VERSION ""

NS_ :

BS_:

BU_: BMSMaster Converter CoolingBack CoolingLeft CoolingMotor CoolingRight Dashboard EngineLeft JETSON LightsFR LightsFL LightsRR LightsRL MPPT Pedals RCD SafeState SensorFR SensorFL SensorRR SensorRL SmallBMS Charger1 Charger2 Charger3 EngineRight CoolingLeft CoolingRight CoolingBack CoolingMotor

BO_ 3221225472 VECTOR__INDEPENDENT_SIG_MSG: 0 Vector__XXX
 SG_ BMSMaster_MasterBatteryCurrent : 23|8@0+ (0.1465,300) [-300|300] "A" Vector__XXX
 SG_ BMSMaster_MasterBatteryVoltage : 15|8@0+ (0.0059,12) [63|87] "V" Vector__XXX
 SG_ BMSMaster_MasterBatteryTemp_0000 : 47|8@0+ (0.024,50) [0|100] "C" Vector__XXX
 SG_ BMSMaster_ErrorCodeBL : 23|8@0+ (1,0) [256|65535] "" Vector__XXX
 SG_ NewSignal_0003 : 16|8@1+ (1,0) [0|0] "" Vector__XXX
 SG_ NewSignal_0002 : 8|1@1+ (1,0) [0|0] "" Vector__XXX
 SG_ NewSignal_0001 : 0|1@1+ (1,0) [0|0] "" Vector__XXX

BO_ 1952 LightsRL_NODE: 8 LightsRL

BO_ 1920 LightsRR_NODE: 8 LightsRR

BO_ 1888 LightsFL_NODE: 8 LightsFL

BO_ 1856 LightsFR_NODE: 8 LightsFR

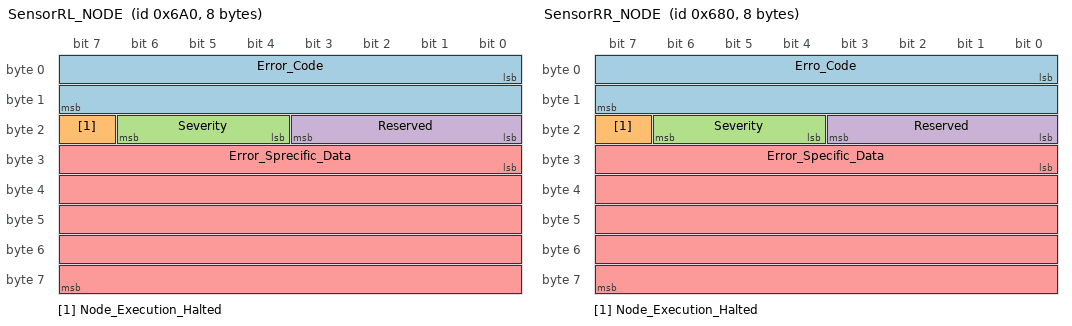
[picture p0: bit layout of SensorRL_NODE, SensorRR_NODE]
BO_ 1696 SensorRL_NODE: 8 SensorRL
 SG_ Error_Code : 0|16@1+ (1,0) [0|0] "" Vector__XXX
 SG_ Node_Execution_Halted : 23|1@1+ (1,0) [0|0] "" Vector__XXX
 SG_ Severity : 20|3@1+ (1,0) [0|0] "" Vector__XXX
 SG_ Reserved : 16|4@1+ (1,0) [0|0] "" Vector__XXX
 SG_ Error_Sprecific_Data : 24|40@1+ (1,0) [0|0] "" Vector__XXX

BO_ 1664 SensorRR_NODE: 8 SensorRR
 SG_ Erro_Code : 0|16@1+ (1,0) [0|0] "" Vector__XXX
 SG_ Node_Execution_Halted : 23|1@1+ (1,0) [0|0] "" Vector__XXX
 SG_ Severity : 20|3@1+ (1,0) [0|0] "" Vector__XXX
 SG_ Reserved : 16|4@1+ (1,0) [0|0] "" Vector__XXX
 SG_ Error_Specific_Data : 24|40@1+ (1,0) [0|0] "" Vector__XXX

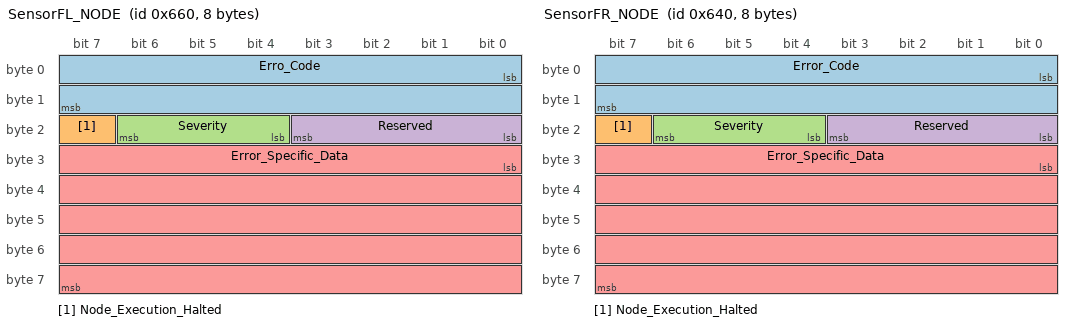
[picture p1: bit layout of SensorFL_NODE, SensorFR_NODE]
BO_ 1632 SensorFL_NODE: 8 SensorFL
 SG_ Erro_Code : 0|16@1+ (1,0) [0|0] "" Vector__XXX
 SG_ Node_Execution_Halted : 23|1@1+ (1,0) [0|0] "" Vector__XXX
 SG_ Severity : 20|3@1+ (1,0) [0|0] "" Vector__XXX
 SG_ Reserved : 16|4@1+ (1,0) [0|0] "" Vector__XXX
 SG_ Error_Specific_Data : 24|40@1+ (1,0) [0|0] "" Vector__XXX

BO_ 1600 SensorFR_NODE: 8 SensorFR
 SG_ Error_Code : 0|16@1+ (1,0) [0|0] "" Vector__XXX
 SG_ Node_Execution_Halted : 23|1@1+ (1,0) [0|0] "" Vector__XXX
 SG_ Severity : 20|3@1+ (1,0) [0|0] "" Vector__XXX
 SG_ Reserved : 16|4@1+ (1,0) [0|0] "" Vector__XXX
 SG_ Error_Specific_Data : 24|40@1+ (1,0) [0|0] "" Vector__XXX

BO_ 1472 LowVoltConverter_NODE: 8 Converter

BO_ 1120 MPPT_NODE: 8 MPPT

BO_ 864 SmallBMS_NODE: 8 SmallBMS

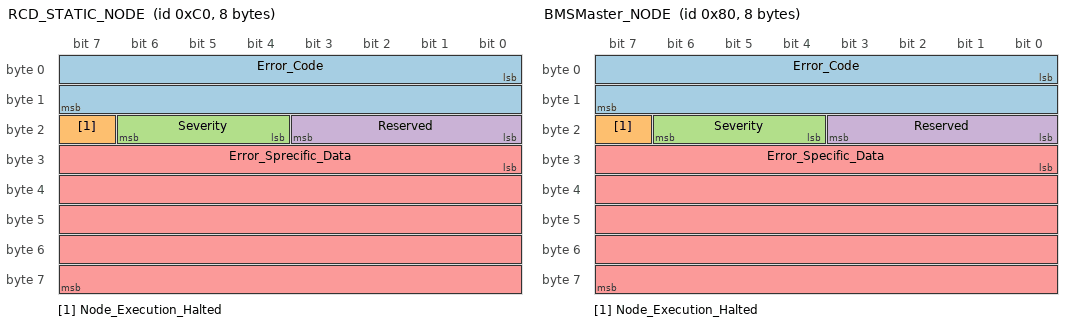
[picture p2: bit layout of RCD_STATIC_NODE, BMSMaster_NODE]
BO_ 192 RCD_STATIC_NODE: 8 RCD
 SG_ Error_Code : 0|16@1+ (1,0) [0|0] "" Vector__XXX
 SG_ Node_Execution_Halted : 23|1@1+ (1,0) [0|0] "" Vector__XXX
 SG_ Severity : 20|3@1+ (1,0) [0|0] "" Vector__XXX
 SG_ Reserved : 16|4@1+ (1,0) [0|0] "" Vector__XXX
 SG_ Error_Sprecific_Data : 24|40@1+ (1,0) [0|0] "" Vector__XXX

BO_ 128 BMSMaster_NODE: 8 BMSMaster
 SG_ Error_Code : 0|16@1+ (1,0) [0|0] "" Vector__XXX
 SG_ Node_Execution_Halted : 23|1@1+ (1,0) [0|0] "" Vector__XXX
 SG_ Severity : 20|3@1+ (1,0) [0|0] "" Vector__XXX
 SG_ Reserved : 16|4@1+ (1,0) [0|0] "" Vector__XXX
 SG_ Error_Specific_Data : 24|40@1+ (1,0) [0|0] "" Vector__XXX

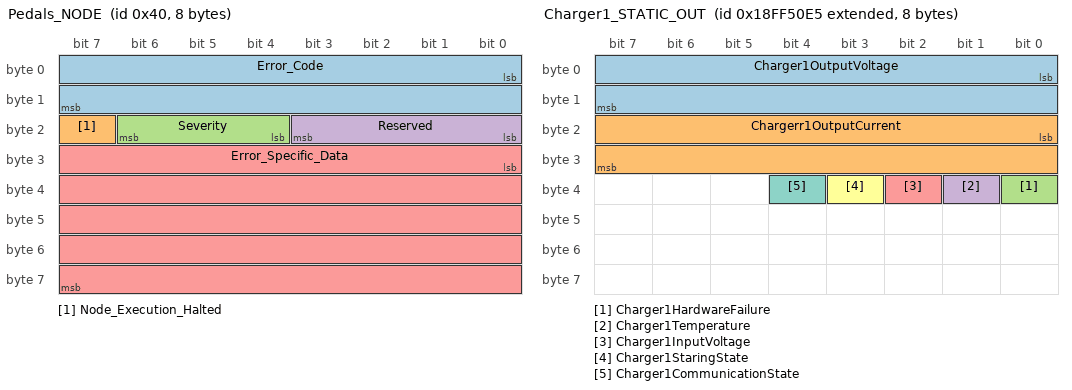
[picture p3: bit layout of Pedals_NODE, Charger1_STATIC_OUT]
BO_ 64 Pedals_NODE: 8 Pedals
 SG_ Error_Code : 0|16@1+ (1,0) [0|0] "" Vector__XXX
 SG_ Node_Execution_Halted : 23|1@1+ (1,0) [0|0] "" Vector__XXX
 SG_ Severity : 20|3@1+ (1,0) [0|0] "" Vector__XXX
 SG_ Reserved : 16|4@1+ (1,0) [0|0] "" Vector__XXX
 SG_ Error_Specific_Data : 24|40@1+ (1,0) [0|0] "" Vector__XXX

BO_ 512 JETSON_STATIC_NODE: 8 JETSON

BO_ 1 SafeState_NODE: 8 SafeState

BO_ 1983 LightsRL_END: 8 LightsRL

BO_ 1727 SensorRL_END: 8 SensorRL

BO_ 1951 LightsRR_END: 8 LightsRR

BO_ 31 SafeState_END: 8 SafeState

BO_ 95 Pedals_END: 8 Pedals

BO_ 159 BMSMaster_END: 8 BMSMaster

BO_ 223 RCD_STATIC_END: 8 RCD

BO_ 543 JETSON_STATIC_END: 8 JETSON

BO_ 895 SmallBMS_END: 8 SmallBMS

BO_ 1503 LowVoltConverter_END: 8 Converter

BO_ 1279 CoolingBack_END: 8 CoolingBack

BO_ 1311 CoolingLeft_END: 8 CoolingLeft

BO_ 1375 CoolingMotor_END: 8 CoolingMotor

BO_ 1343 CoolingRight_END: 8 CoolingRight

BO_ 1151 MPPT_END: 8 MPPT

BO_ 1653 SensorFL_END: 8 SensorFL

BO_ 1631 SensorFR_END: 8 SensorFR

BO_ 1695 SensorRR_END: 8 SensorRR

BO_ 1919 LightsFL_END: 8 LightsFL

BO_ 1887 LightsFR_END: 8 LightsFR

BO_ 2566869221 Charger1_STATIC_OUT: 8 Charger1
 SG_ Charger1OutputVoltage : 0|16@1+ (0.1,0) [440|990] "V" Vector__XXX
 SG_ Chargerr1OutputCurrent : 16|16@1+ (0.1,0) [0|400] "A" Vector__XXX
 SG_ Charger1HardwareFailure : 32|1@1+ (1,0) [0|0] "" Vector__XXX
 SG_ Charger1Temperature : 33|1@1+ (1,0) [0|0] "" Vector__XXX
 SG_ Charger1InputVoltage : 34|1@1+ (1,0) [0|0] "" Vector__XXX
 SG_ Charger1StaringState : 35|1@1+ (1,0) [0|0] "" Vector__XXX
 SG_ Charger1CommunicationState : 36|1@1+ (1,0) [0|0] "" Vector__XXX

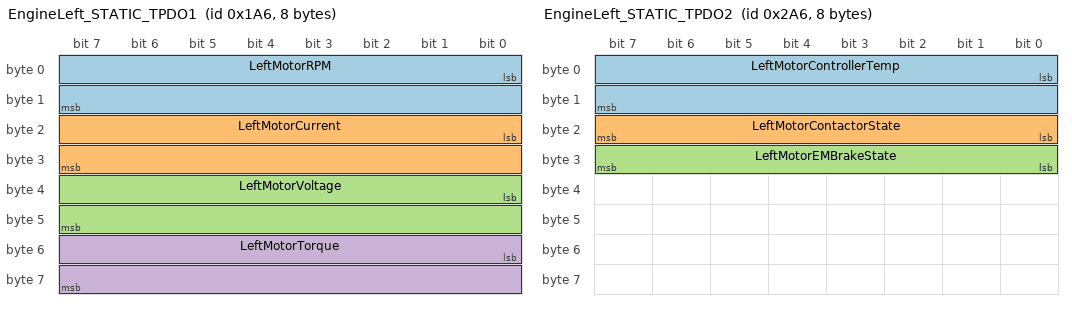
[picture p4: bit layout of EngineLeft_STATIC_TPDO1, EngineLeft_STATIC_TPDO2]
BO_ 422 EngineLeft_STATIC_TPDO1: 8 EngineLeft
 SG_ LeftMotorRPM : 0|16@1- (1,0) [-30000|30000] "rpm" Vector__XXX
 SG_ LeftMotorCurrent : 16|16@1- (0.1,0) [-32768|32767] "A" Vector__XXX
 SG_ LeftMotorVoltage : 32|16@1+ (0.01,0) [0|10500] "V" Vector__XXX
 SG_ LeftMotorTorque : 48|16@1- (1,0) [-500|500] "Nm" Vector__XXX

BO_ 678 EngineLeft_STATIC_TPDO2: 8 EngineLeft
 SG_ LeftMotorControllerTemp : 0|16@1- (0.1,0) [-1000|3000] "C" Vector__XXX
 SG_ LeftMotorContactorState : 16|8@1+ (1,0) [0|10] "" Vector__XXX
 SG_ LeftMotorEMBrakeState : 24|8@1+ (1,0) [0|4] "" Vector__XXX

BO_ 1830 EngineLeft_STATIC_NMT: 1 EngineLeft
 SG_ LeftMotorNMTState : 0|8@1+ (1,0) [0|255] "" Vector__XXX

BO_ 166 EngineLeft_STATIC_EMCY: 8 EngineLeft
 SG_ LeftMotorErrorMsg : 0|8@1+ (1,0) [0|0] "" Vector__XXX

BO_ 550 JETSON_STATIC_EngineLeft_RPDO1: 8 JETSON
 SG_ LeftMotorThrottleComand : 0|16@1- (1,0) [-32768|32767] "" Vector__XXX

BO_ 167 EngineRight_STATIC_EMCY: 8 EngineRight
 SG_ RightMotorErrorMsg : 0|8@1+ (1,0) [0|0] "" Vector__XXX

BO_ 1831 EngineRight_STATIC_NMT: 1 EngineRight
 SG_ RightMotorNMTState : 0|8@1+ (1,0) [0|255] "" Vector__XXX

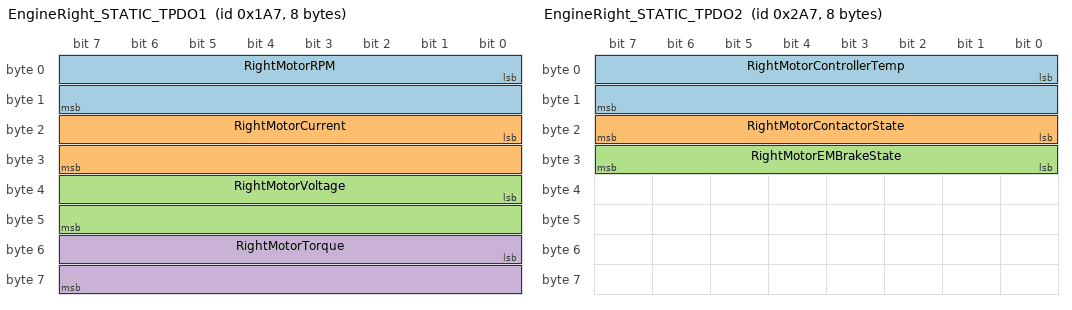
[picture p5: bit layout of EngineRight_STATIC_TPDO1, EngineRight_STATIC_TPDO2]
BO_ 423 EngineRight_STATIC_TPDO1: 8 EngineRight
 SG_ RightMotorRPM : 0|16@1- (1,0) [-30000|30000] "rpm" Vector__XXX
 SG_ RightMotorCurrent : 16|16@1- (0.1,0) [-32768|32767] "A" Vector__XXX
 SG_ RightMotorVoltage : 32|16@1+ (0.01,0) [0|10500] "V" Vector__XXX
 SG_ RightMotorTorque : 48|16@1- (1,0) [-500|500] "Nm" Vector__XXX

BO_ 679 EngineRight_STATIC_TPDO2: 8 EngineRight
 SG_ RightMotorControllerTemp : 0|16@1- (0.1,0) [-1000|3000] "C" Vector__XXX
 SG_ RightMotorContactorState : 16|8@1+ (1,0) [0|10] "" Vector__XXX
 SG_ RightMotorEMBrakeState : 24|8@1+ (1,0) [0|4] "" Vector__XXX

BO_ 551 JETSON_STATIC_EngineRight_RPDO1: 8 JETSON
 SG_ RightMotorThrottleComand : 0|16@1- (1,0) [-32768|32767] "" Vector__XXX

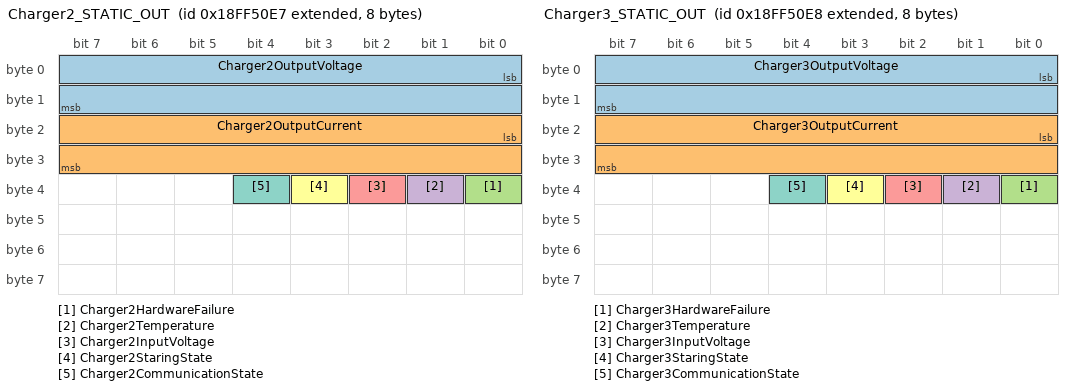
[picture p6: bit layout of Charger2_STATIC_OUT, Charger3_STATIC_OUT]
BO_ 2566869223 Charger2_STATIC_OUT: 8 Charger2
 SG_ Charger2OutputVoltage : 0|16@1+ (0.1,0) [440|900] "V" Vector__XXX
 SG_ Charger2OutputCurrent : 16|16@1+ (0.1,0) [0|400] "A" Vector__XXX
 SG_ Charger2HardwareFailure : 32|1@1+ (1,0) [0|0] "" Vector__XXX
 SG_ Charger2Temperature : 33|1@1+ (1,0) [0|0] "" Vector__XXX
 SG_ Charger2InputVoltage : 34|1@1+ (1,0) [0|0] "" Vector__XXX
 SG_ Charger2StaringState : 35|1@1+ (1,0) [0|0] "" Vector__XXX
 SG_ Charger2CommunicationState : 36|1@1+ (1,0) [0|0] "" Vector__XXX

BO_ 2566869224 Charger3_STATIC_OUT: 8 Charger3
 SG_ Charger3OutputVoltage : 0|16@1+ (0.1,0) [440|990] "V" Vector__XXX
 SG_ Charger3OutputCurrent : 16|16@1+ (0.1,0) [0|400] "A" Vector__XXX
 SG_ Charger3HardwareFailure : 32|1@1+ (1,0) [0|0] "" Vector__XXX
 SG_ Charger3Temperature : 33|1@1+ (1,0) [0|0] "" Vector__XXX
 SG_ Charger3InputVoltage : 34|1@1+ (1,0) [0|0] "" Vector__XXX
 SG_ Charger3StaringState : 35|1@1+ (1,0) [0|0] "" Vector__XXX
 SG_ Charger3CommunicationState : 36|1@1+ (1,0) [0|0] "" Vector__XXX

BO_ 2550588916 RCD_STATIC_Charger1Comms: 8 RCD
 SG_ MaxChargVolt : 7|16@0+ (0.1,0) [0|0] "V" Vector__XXX
 SG_ MaxChargCurr : 23|16@0+ (0.1,0) [0|0] "A" Vector__XXX
 SG_ Control : 39|8@0+ (0.1,0) [0|0] "" Vector__XXX

BO_ 2550589428 RCD_STATIC_Charger2Comms: 8 RCD
 SG_ MaxChargVolt : 7|16@0+ (0.1,0) [0|0] "V" Vector__XXX
 SG_ MaxChargCurr : 23|16@0+ (0.1,0) [0|0] "A" Vector__XXX
 SG_ Control : 39|8@0+ (0.1,0) [0|0] "" Vector__XXX

BO_ 2550589684 RCD_STATIC_Charger3Comms: 8 RCD
 SG_ MaxChargVolt : 7|16@0+ (0.1,0) [0|0] "V" Vector__XXX
 SG_ MaxChargCurr : 23|16@0+ (0.1,0) [0|0] "A" Vector__XXX
 SG_ Control : 39|8@0+ (0.1,0) [0|0] "" Vector__XXX

BO_ 130 BMSMaster_MasterVoltCurrTemp: 6 BMSMaster
 SG_ BMSMaster_MasterBatteryVoltage : 0|16@1+ (0.1,0) [63|87] "V"  RCD
 SG_ BMSMaster_MasterBatteryCurrent : 16|16@1- (0.1,0) [-300|300] "A"  RCD
 SG_ BMSMaste_MasterBatteryTemperatur : 32|16@1+ (0.01,0) [0|100] "C"  RCD

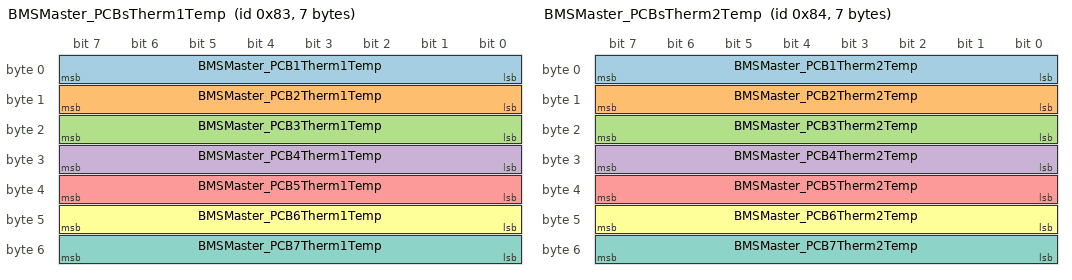
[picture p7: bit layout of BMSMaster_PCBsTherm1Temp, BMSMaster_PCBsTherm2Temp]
BO_ 131 BMSMaster_PCBsTherm1Temp: 7 BMSMaster
 SG_ BMSMaster_PCB1Therm1Temp : 0|8@1+ (0.39216,49.8039) [0|100] "C" Vector__XXX
 SG_ BMSMaster_PCB2Therm1Temp : 8|8@1+ (0.39216,49.8039) [0|100] "C" Vector__XXX
 SG_ BMSMaster_PCB3Therm1Temp : 16|8@1+ (0.39216,49.8039) [0|100] "C" Vector__XXX
 SG_ BMSMaster_PCB4Therm1Temp : 24|8@1+ (0.39216,49.8039) [0|100] "C" Vector__XXX
 SG_ BMSMaster_PCB5Therm1Temp : 32|8@1+ (0.39216,49.8039) [0|100] "C" Vector__XXX
 SG_ BMSMaster_PCB6Therm1Temp : 40|8@1+ (0.39216,49.8039) [0|100] "C" Vector__XXX
 SG_ BMSMaster_PCB7Therm1Temp : 48|8@1+ (0.39216,49.8039) [0|100] "C" Vector__XXX

BO_ 132 BMSMaster_PCBsTherm2Temp: 7 BMSMaster
 SG_ BMSMaster_PCB1Therm2Temp : 0|8@1+ (0.39216,49.8039) [0|100] "C" Vector__XXX
 SG_ BMSMaster_PCB2Therm2Temp : 8|8@1+ (0.39216,49.8039) [0|100] "C" Vector__XXX
 SG_ BMSMaster_PCB3Therm2Temp : 16|8@1+ (0.39216,49.8039) [0|100] "C" Vector__XXX
 SG_ BMSMaster_PCB4Therm2Temp : 24|8@1+ (0.39216,49.8039) [0|100] "C" Vector__XXX
 SG_ BMSMaster_PCB5Therm2Temp : 32|8@1+ (0.39216,49.8039) [0|100] "C" Vector__XXX
 SG_ BMSMaster_PCB6Therm2Temp : 40|8@1+ (0.39216,49.8039) [0|100] "C" Vector__XXX
 SG_ BMSMaster_PCB7Therm2Temp : 48|8@1+ (0.39216,49.8039) [0|100] "C" Vector__XXX

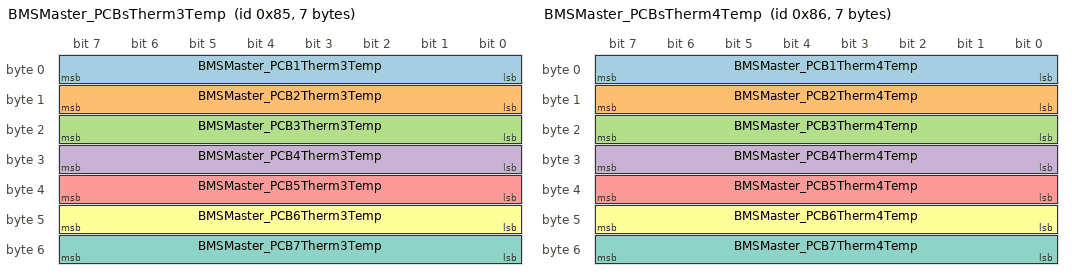
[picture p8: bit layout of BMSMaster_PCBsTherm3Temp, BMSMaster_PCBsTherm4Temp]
BO_ 133 BMSMaster_PCBsTherm3Temp: 7 BMSMaster
 SG_ BMSMaster_PCB1Therm3Temp : 0|8@1+ (0.39216,49) [0|100] "C" Vector__XXX
 SG_ BMSMaster_PCB2Therm3Temp : 8|8@1+ (0.39216,49) [0|100] "C" Vector__XXX
 SG_ BMSMaster_PCB3Therm3Temp : 16|8@1+ (0.39216,49) [0|100] "C" Vector__XXX
 SG_ BMSMaster_PCB4Therm3Temp : 24|8@1+ (0.39216,49) [0|100] "C" Vector__XXX
 SG_ BMSMaster_PCB5Therm3Temp : 32|8@1+ (0.39216,49) [0|100] "C" Vector__XXX
 SG_ BMSMaster_PCB6Therm3Temp : 40|8@1+ (0.39216,49) [0|100] "C" Vector__XXX
 SG_ BMSMaster_PCB7Therm3Temp : 48|8@1+ (0.39216,49) [0|100] "C" Vector__XXX

BO_ 134 BMSMaster_PCBsTherm4Temp: 7 BMSMaster
 SG_ BMSMaster_PCB1Therm4Temp : 0|8@1+ (0.39216,49.8039) [0|100] "C" Vector__XXX
 SG_ BMSMaster_PCB2Therm4Temp : 8|8@1+ (0.39216,49.8039) [0|100] "C" Vector__XXX
 SG_ BMSMaster_PCB3Therm4Temp : 16|8@1+ (0.39216,49.8039) [0|100] "C" Vector__XXX
 SG_ BMSMaster_PCB4Therm4Temp : 24|8@1+ (0.39216,49.8039) [0|100] "C" Vector__XXX
 SG_ BMSMaster_PCB5Therm4Temp : 32|8@1+ (0.39216,49.8039) [0|100] "C" Vector__XXX
 SG_ BMSMaster_PCB6Therm4Temp : 40|8@1+ (0.39216,49.8039) [0|100] "C" Vector__XXX
 SG_ BMSMaster_PCB7Therm4Temp : 48|8@1+ (0.39216,49.8039) [0|100] "C" Vector__XXX

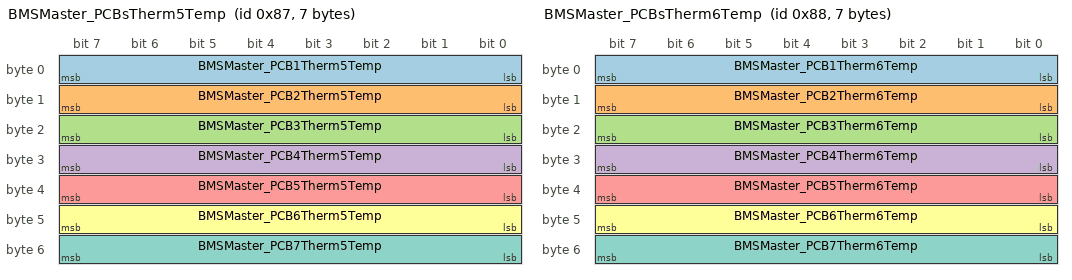
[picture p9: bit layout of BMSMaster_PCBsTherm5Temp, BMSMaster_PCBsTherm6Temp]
BO_ 135 BMSMaster_PCBsTherm5Temp: 7 BMSMaster
 SG_ BMSMaster_PCB1Therm5Temp : 0|8@1+ (0.39216,49.8039) [0|100] "C" Vector__XXX
 SG_ BMSMaster_PCB2Therm5Temp : 8|8@1+ (0.39216,49.8039) [0|100] "C" Vector__XXX
 SG_ BMSMaster_PCB3Therm5Temp : 16|8@1+ (0.39216,49.8039) [0|100] "C" Vector__XXX
 SG_ BMSMaster_PCB4Therm5Temp : 24|8@1+ (0.39216,49.8039) [0|100] "C" Vector__XXX
 SG_ BMSMaster_PCB5Therm5Temp : 32|8@1+ (0.39216,49.8039) [0|100] "C" Vector__XXX
 SG_ BMSMaster_PCB6Therm5Temp : 40|8@1+ (0.39216,49.8039) [0|100] "C" Vector__XXX
 SG_ BMSMaster_PCB7Therm5Temp : 48|8@1+ (0.39216,49.8039) [0|100] "C" Vector__XXX

BO_ 136 BMSMaster_PCBsTherm6Temp: 7 BMSMaster
 SG_ BMSMaster_PCB1Therm6Temp : 0|8@1+ (0.39216,49.8039) [0|100] "C" Vector__XXX
 SG_ BMSMaster_PCB2Therm6Temp : 8|8@1+ (0.39216,49.8039) [0|100] "C" Vector__XXX
 SG_ BMSMaster_PCB3Therm6Temp : 16|8@1+ (0.39216,49.8039) [0|100] "C" Vector__XXX
 SG_ BMSMaster_PCB4Therm6Temp : 24|8@1+ (0.39216,49.8039) [0|100] "C" Vector__XXX
 SG_ BMSMaster_PCB5Therm6Temp : 32|8@1+ (0.39216,49.8039) [0|100] "C" Vector__XXX
 SG_ BMSMaster_PCB6Therm6Temp : 40|8@1+ (0.39216,49.8039) [0|100] "C" Vector__XXX
 SG_ BMSMaster_PCB7Therm6Temp : 48|8@1+ (0.39216,49.8039) [0|100] "C" Vector__XXX

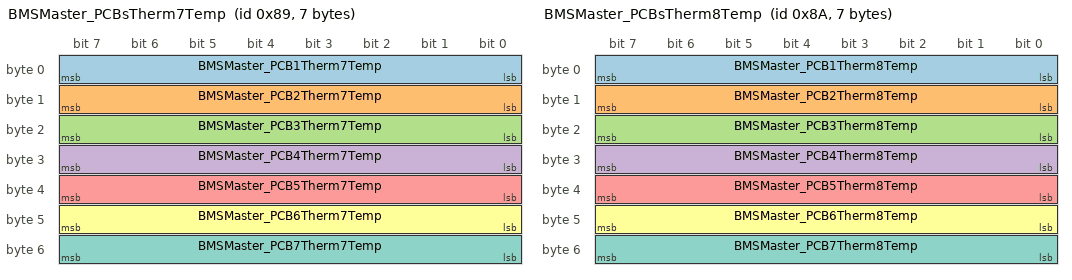
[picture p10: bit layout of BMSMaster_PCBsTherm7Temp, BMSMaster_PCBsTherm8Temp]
BO_ 137 BMSMaster_PCBsTherm7Temp: 7 BMSMaster
 SG_ BMSMaster_PCB1Therm7Temp : 0|8@1+ (0.39216,49) [0|100] "C" Vector__XXX
 SG_ BMSMaster_PCB2Therm7Temp : 8|8@1+ (0.39216,49.8039) [0|100] "C" Vector__XXX
 SG_ BMSMaster_PCB3Therm7Temp : 16|8@1+ (0.39216,49.8039) [0|100] "C" Vector__XXX
 SG_ BMSMaster_PCB4Therm7Temp : 24|8@1+ (0.39216,49.8039) [0|100] "C" Vector__XXX
 SG_ BMSMaster_PCB5Therm7Temp : 32|8@1+ (0.39216,49.8039) [0|100] "C" Vector__XXX
 SG_ BMSMaster_PCB6Therm7Temp : 40|8@1+ (0.39216,49.8039) [0|100] "C" Vector__XXX
 SG_ BMSMaster_PCB7Therm7Temp : 48|8@1+ (0.39216,49.8039) [0|100] "C" Vector__XXX

BO_ 138 BMSMaster_PCBsTherm8Temp: 7 BMSMaster
 SG_ BMSMaster_PCB1Therm8Temp : 0|8@1+ (0.39216,49) [0|100] "C" Vector__XXX
 SG_ BMSMaster_PCB2Therm8Temp : 8|8@1+ (0.39216,49) [0|100] "C" Vector__XXX
 SG_ BMSMaster_PCB3Therm8Temp : 16|8@1+ (0.39216,49) [0|100] "C" Vector__XXX
 SG_ BMSMaster_PCB4Therm8Temp : 24|8@1+ (0.39216,49) [0|100] "C" Vector__XXX
 SG_ BMSMaster_PCB5Therm8Temp : 32|8@1+ (0.39216,49) [0|100] "C" Vector__XXX
 SG_ BMSMaster_PCB6Therm8Temp : 40|8@1+ (0.39216,49) [0|100] "C" Vector__XXX
 SG_ BMSMaster_PCB7Therm8Temp : 48|8@1+ (0.39216,49) [0|100] "C" Vector__XXX

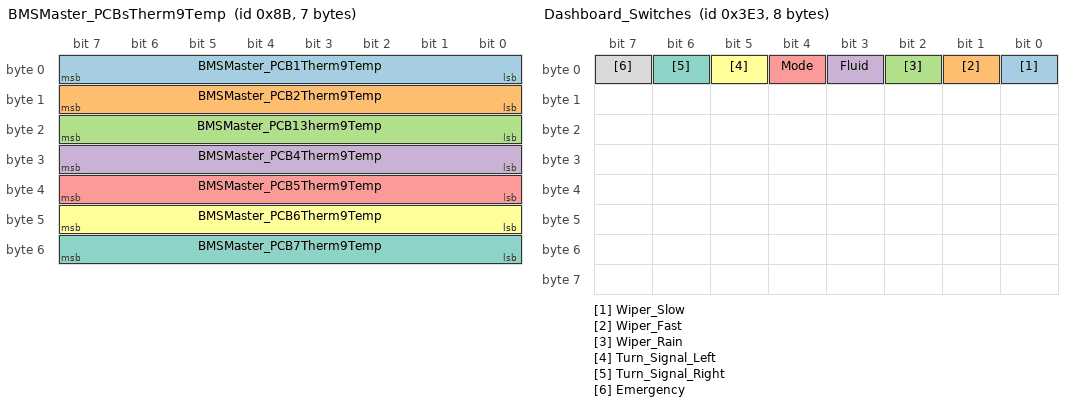
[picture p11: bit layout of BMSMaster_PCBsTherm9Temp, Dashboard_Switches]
BO_ 139 BMSMaster_PCBsTherm9Temp: 7 BMSMaster
 SG_ BMSMaster_PCB1Therm9Temp : 0|8@1+ (0.39216,49) [0|100] "C" Vector__XXX
 SG_ BMSMaster_PCB2Therm9Temp : 8|8@1+ (0.39216,49) [0|100] "C" Vector__XXX
 SG_ BMSMaster_PCB13herm9Temp : 16|8@1+ (0.39216,49) [0|100] "C" Vector__XXX
 SG_ BMSMaster_PCB4Therm9Temp : 24|8@1+ (0.39216,49) [0|100] "C" Vector__XXX
 SG_ BMSMaster_PCB5Therm9Temp : 32|8@1+ (0.39216,49) [0|100] "C" Vector__XXX
 SG_ BMSMaster_PCB6Therm9Temp : 40|8@1+ (0.39216,49) [0|100] "C" Vector__XXX
 SG_ BMSMaster_PCB7Therm9Temp : 48|8@1+ (0.39216,49) [0|100] "C" Vector__XXX

BO_ 993 Dashboard_Control: 8 Dashboard
 SG_ Absolute_Encoder : 0|14@1+ (0.06591796875,540) [-540|540] "deg"  RCD
 SG_ PRND : 14|8@1+ (1,0) [0|3] ""  RCD

BO_ 994 Dashboard_Important: 8 Dashboard
 SG_ Light_Switch : 0|8@1+ (1,0) [0|3] "" Vector__XXX
 SG_ Rain_Level : 8|8@1+ (1,0) [0|4] "" Vector__XXX

BO_ 995 Dashboard_Switches: 8 Dashboard
 SG_ Wiper_Slow : 0|1@1+ (1,0) [0|1] "" Vector__XXX
 SG_ Wiper_Fast : 1|1@1+ (1,0) [0|1] "" Vector__XXX
 SG_ Wiper_Rain : 2|1@1+ (1,0) [0|1] "" Vector__XXX
 SG_ Fluid : 3|1@1+ (1,0) [0|1] "" Vector__XXX
 SG_ Mode : 4|1@1+ (1,0) [0|1] "" Vector__XXX
 SG_ Turn_Signal_Left : 5|1@1+ (1,0) [0|3] "" Vector__XXX
 SG_ Turn_Signal_Right : 6|1@1+ (1,0) [0|0] "" Vector__XXX
 SG_ Emergency : 7|1@1+ (1,0) [0|1] "" Vector__XXX

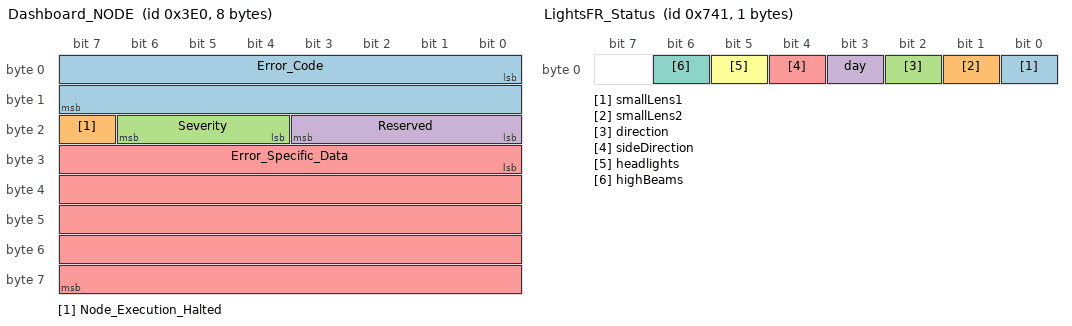
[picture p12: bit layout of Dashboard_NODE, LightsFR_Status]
BO_ 992 Dashboard_NODE: 8 Dashboard
 SG_ Error_Code : 0|16@1+ (1,0) [0|0] "" Vector__XXX
 SG_ Node_Execution_Halted : 23|1@1+ (1,0) [0|0] "" Vector__XXX
 SG_ Severity : 20|3@1+ (1,0) [0|0] "" Vector__XXX
 SG_ Reserved : 16|4@1+ (1,0) [0|0] "" Vector__XXX
 SG_ Error_Specific_Data : 24|40@1+ (1,0) [0|0] "" Vector__XXX

BO_ 1023 Dashboard_END: 8 Dashboard

BO_ 1857 LightsFR_Status: 1 LightsFR
 SG_ smallLens1 : 0|1@1+ (1,0) [0|0] "" Vector__XXX
 SG_ smallLens2 : 1|1@1+ (1,0) [0|0] "" Vector__XXX
 SG_ direction : 2|1@1+ (1,0) [0|0] "" Vector__XXX
 SG_ day : 3|1@1+ (1,0) [0|0] "" Vector__XXX
 SG_ sideDirection : 4|1@1+ (1,0) [0|0] "" Vector__XXX
 SG_ headlights : 5|1@1+ (1,0) [0|0] "" Vector__XXX
 SG_ highBeams : 6|1@1+ (1,0) [0|0] "" Vector__XXX

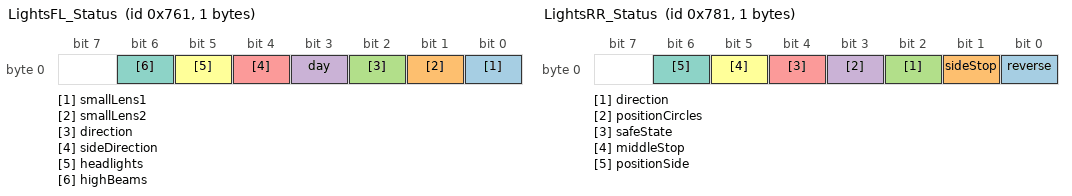
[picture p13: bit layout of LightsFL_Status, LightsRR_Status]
BO_ 1889 LightsFL_Status: 1 LightsFL
 SG_ smallLens1 : 0|1@1+ (1,0) [0|0] "" Vector__XXX
 SG_ smallLens2 : 1|1@1+ (1,0) [0|0] "" Vector__XXX
 SG_ direction : 2|1@1+ (1,0) [0|0] "" Vector__XXX
 SG_ day : 3|1@1+ (1,0) [0|0] "" Vector__XXX
 SG_ sideDirection : 4|1@1+ (1,0) [0|0] "" Vector__XXX
 SG_ headlights : 5|1@1+ (1,0) [0|0] "" Vector__XXX
 SG_ highBeams : 6|1@1+ (1,0) [0|0] "" Vector__XXX

BO_ 1921 LightsRR_Status: 1 LightsRR
 SG_ reverse : 0|1@1+ (1,0) [0|0] "" Vector__XXX
 SG_ sideStop : 1|1@1+ (1,0) [0|0] "" Vector__XXX
 SG_ direction : 2|1@1+ (1,0) [0|0] "" Vector__XXX
 SG_ positionCircles : 3|1@1+ (1,0) [0|0] "" Vector__XXX
 SG_ safeState : 4|1@1+ (1,0) [0|0] "" Vector__XXX
 SG_ middleStop : 5|1@1+ (1,0) [0|0] "" Vector__XXX
 SG_ positionSide : 6|1@1+ (1,0) [0|0] "" Vector__XXX

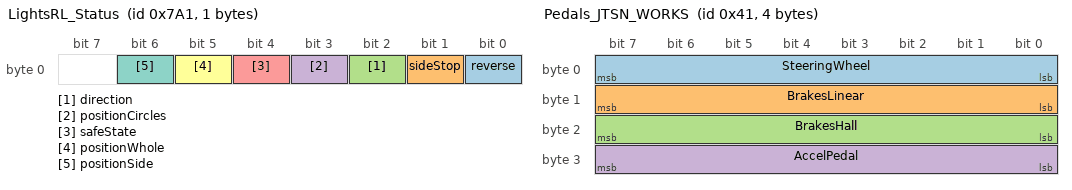
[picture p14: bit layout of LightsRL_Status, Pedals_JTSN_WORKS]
BO_ 1953 LightsRL_Status: 1 LightsRL
 SG_ reverse : 0|1@1+ (1,0) [0|0] "" Vector__XXX
 SG_ sideStop : 1|1@1+ (1,0) [0|0] "" Vector__XXX
 SG_ direction : 2|1@1+ (1,0) [0|0] "" Vector__XXX
 SG_ positionCircles : 3|1@1+ (1,0) [0|0] "" Vector__XXX
 SG_ safeState : 4|1@1+ (1,0) [0|0] "" Vector__XXX
 SG_ positionWhole : 5|1@1+ (1,0) [0|0] "" Vector__XXX
 SG_ positionSide : 6|1@1+ (1,0) [0|0] "" Vector__XXX

BO_ 1601 SensorFR_Wheel_Speed: 2 SensorFR
 SG_ SensorFR_Wheel_Speed : 0|16@1+ (0.000839,0) [0|55] "m/s" Vector__XXX

BO_ 1602 SensorFR_Suspension: 2 SensorFR
 SG_ SensorFR_Suspension : 0|16@1+ (0.02,0) [0|75] "mm" Vector__XXX

BO_ 1603 SensorFR_Door_Sensor: 1 SensorFR
 SG_ SensorFR_Door_Sensor : 0|1@1+ (1,0) [0|1] "" Vector__XXX

BO_ 1633 SensorFL_Wheel_Speed: 2 SensorFL
 SG_ SensorFL_Wheel_Speed : 0|16@1+ (0.000839,0) [0|55] "m/s" Vector__XXX

BO_ 1634 SensorFL_Suspension: 2 SensorFL
 SG_ SensorFL_Suspension : 0|16@1+ (0.02,0) [0|75] "mm" Vector__XXX

BO_ 1635 SensorFL_Door_Sensor: 1 SensorFL
 SG_ SensorFL_Door_Sensor : 0|1@1+ (1,0) [0|1] "" Vector__XXX

BO_ 1665 SensorRR_Wheel_Speed: 2 SensorRR
 SG_ SensorRR_Wheel_Speed : 0|16@1+ (0.000839,0) [0|55] "m/s" Vector__XXX

BO_ 1666 SensorRR_Suspension: 2 SensorRR
 SG_ SensorRR_Suspension : 0|16@1+ (0.02,0) [0|75] "mm" Vector__XXX

BO_ 1667 SensorRR_Door_Sensor: 1 SensorRR
 SG_ SensorRR_Door_Sensor : 0|1@1+ (1,0) [0|1] "" Vector__XXX

BO_ 1697 SensorRL_Wheel_Speed: 2 SensorRL
 SG_ SensorRL_Wheel_Speed : 0|16@1+ (0.000839,0) [0|55] "m/s" Vector__XXX

BO_ 1698 SensorRL_Suspension: 2 SensorRL
 SG_ SensorRL_Suspension : 0|16@1+ (0.02,0) [0|55] "m/s" Vector__XXX

BO_ 1699 SensorRL_Door_Sensor: 1 SensorRL
 SG_ SensorRL_Door_Sensor : 0|1@1+ (1,0) [0|1] "" Vector__XXX

BO_ 65 Pedals_JTSN_WORKS: 4 Pedals
 SG_ SteeringWheel : 0|8@1+ (1,0) [0|100] "%" Vector__XXX
 SG_ BrakesLinear : 8|8@1+ (1,0) [0|100] "%" Vector__XXX
 SG_ BrakesHall : 16|8@1+ (1,0) [0|100] "%" Vector__XXX
 SG_ AccelPedal : 24|8@1+ (1,0) [0|100] "%" Vector__XXX

BO_ 0 Pedals_STATIC_EnginesNMT: 2 Pedals
 SG_ NMT_Command : 0|8@1+ (1,0) [0|255] "-" Vector__XXX
 SG_ NodeID : 8|8@1+ (1,0) [0|255] "-" Vector__XXX

BO_ 1249 CoolingBack_Fan: 8 CoolingBack
 SG_ CoolingBack_SpeedF1 : 0|8@1+ (1,0) [0|100] "" Vector__XXX
 SG_ CoolingBack_SpeedF2 : 8|8@1+ (1,0) [0|100] "" Vector__XXX

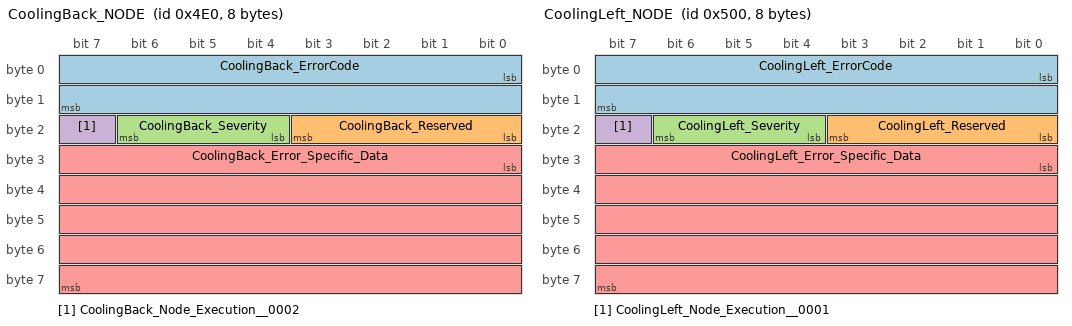
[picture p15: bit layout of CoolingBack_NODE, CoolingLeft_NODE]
BO_ 1248 CoolingBack_NODE: 8 CoolingBack
 SG_ CoolingBack_ErrorCode : 0|16@1+ (1,0) [0|0] "" Vector__XXX
 SG_ CoolingBack_Reserved : 16|4@1+ (1,0) [0|0] "" Vector__XXX
 SG_ CoolingBack_Severity : 20|3@1+ (1,0) [0|0] "" Vector__XXX
 SG_ CoolingBack_Node_Execution__0002 : 23|1@1+ (1,0) [0|0] "" Vector__XXX
 SG_ CoolingBack_Error_Specific_Data : 24|40@1+ (1,0) [0|0] "" Vector__XXX

BO_ 1282 CoolingLeft_Fan: 8 CoolingLeft
 SG_ CoolingLeft_SpeedF1 : 0|8@1+ (1,0) [0|100] "" Vector__XXX
 SG_ CoolingLeft_SpeedF2 : 8|8@1+ (1,0) [0|100] "" Vector__XXX

BO_ 1280 CoolingLeft_NODE: 8 CoolingLeft
 SG_ CoolingLeft_ErrorCode : 0|16@1+ (1,0) [0|0] "" Vector__XXX
 SG_ CoolingLeft_Reserved : 16|4@1+ (1,0) [0|0] "" Vector__XXX
 SG_ CoolingLeft_Severity : 20|3@1+ (1,0) [0|0] "" Vector__XXX
 SG_ CoolingLeft_Node_Execution__0001 : 23|1@1+ (1,0) [0|0] "" Vector__XXX
 SG_ CoolingLeft_Error_Specific_Data : 24|40@1+ (1,0) [0|0] "" Vector__XXX

BO_ 1281 CoolingLeft_Sensor: 8 CoolingLeft
 SG_ CoolingLeft_Sensor_Temp : 0|16@1- (1,0) [-40|80] "C" Vector__XXX
 SG_ CoolingLeft_Sensor_RH : 16|16@1+ (1,0) [0|99.9] "" Vector__XXX

BO_ 1283 CoolingLeft_Serwo: 8 CoolingLeft
 SG_ CoolingLeft_PosSerwo1 : 0|8@1+ (1,0) [0|100] "" Vector__XXX
 SG_ CoolingLeft_PosSerwo2 : 8|8@1+ (1,0) [0|100] "" Vector__XXX

BO_ 1346 CoolingMotor_Fan: 8 CoolingMotor
 SG_ CoolingMotor_SpeedF1 : 0|8@1+ (1,0) [0|100] "" Vector__XXX
 SG_ CoolingMotor_SpeedF2 : 8|8@1+ (1,0) [0|100] "" Vector__XXX

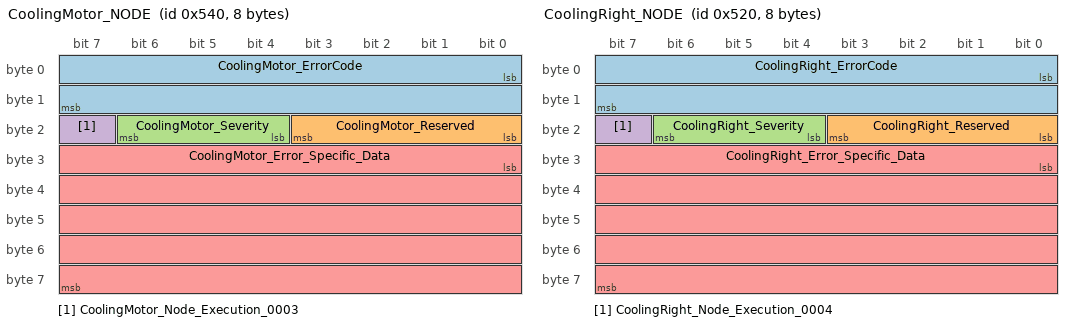
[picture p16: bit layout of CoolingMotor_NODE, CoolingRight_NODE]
BO_ 1344 CoolingMotor_NODE: 8 CoolingMotor
 SG_ CoolingMotor_ErrorCode : 0|16@1+ (1,0) [0|0] "" Vector__XXX
 SG_ CoolingMotor_Reserved : 16|4@1+ (1,0) [0|0] "" Vector__XXX
 SG_ CoolingMotor_Severity : 20|3@1+ (1,0) [0|0] "" Vector__XXX
 SG_ CoolingMotor_Node_Execution_0003 : 23|1@1+ (1,0) [0|0] "" Vector__XXX
 SG_ CoolingMotor_Error_Specific_Data : 24|40@1+ (1,0) [0|0] "" Vector__XXX

BO_ 1345 CoolingMotor_Sensor: 8 CoolingMotor
 SG_ CoolingMotor_Sensor_Temp : 0|16@1- (1,0) [-40|80] "C" Vector__XXX
 SG_ CoolingMotor_Sensor_RH : 16|16@1+ (1,0) [0|99.9] "" Vector__XXX

BO_ 1347 CoolingMotor_Serwo: 8 CoolingMotor
 SG_ CoolingMotor_PosSerwo1 : 0|8@1+ (1,0) [0|100] "" Vector__XXX
 SG_ CoolingMotor_PosSerwo2 : 8|8@1+ (1,0) [0|100] "" Vector__XXX

BO_ 1314 CoolingRight_Fan: 8 CoolingRight
 SG_ CoolingRight_SpeedF1 : 0|8@1+ (1,0) [0|100] "" Vector__XXX
 SG_ CoolingRight_SpeedF2 : 8|8@1+ (1,0) [0|100] "" Vector__XXX

BO_ 1312 CoolingRight_NODE: 8 CoolingRight
 SG_ CoolingRight_ErrorCode : 0|16@1+ (1,0) [0|0] "" Vector__XXX
 SG_ CoolingRight_Reserved : 16|4@1+ (1,0) [0|0] "" Vector__XXX
 SG_ CoolingRight_Severity : 20|3@1+ (1,0) [0|0] "" Vector__XXX
 SG_ CoolingRight_Node_Execution_0004 : 23|1@1+ (1,0) [0|0] "" Vector__XXX
 SG_ CoolingRight_Error_Specific_Data : 24|40@1+ (1,0) [0|0] "" Vector__XXX

BO_ 1313 CoolingRight_Sensor: 8 CoolingRight
 SG_ CoolingRight_Sensor_Temp : 0|16@1- (1,0) [-40|80] "C" Vector__XXX
 SG_ CoolingRight_Sensor_RH : 16|16@1+ (1,0) [0|99.9] "" Vector__XXX

BO_ 1315 CoolingRight_Serwo: 8 CoolingRight
 SG_ CoolingRight_PosSerwo1 : 0|8@1+ (1,0) [0|100] "" Vector__XXX
 SG_ CoolingRight_PosSerwo2 : 8|8@1+ (1,0) [0|100] "" Vector__XXX

BO_ 193 RCD_Status: 8 RCD
 SG_ ChargingPortStatus : 0|2@1+ (1,0) [0|0] "" Vector__XXX

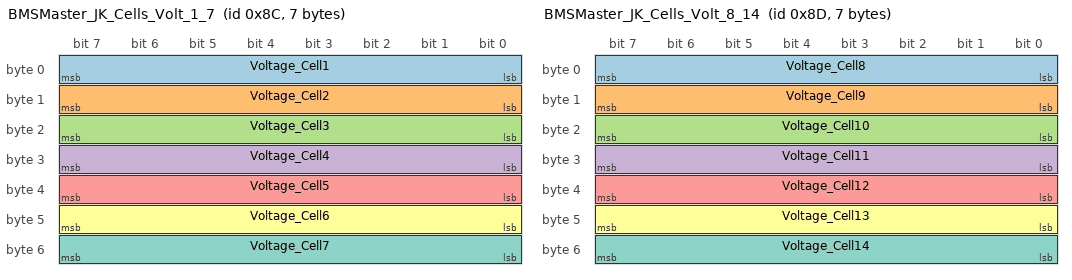
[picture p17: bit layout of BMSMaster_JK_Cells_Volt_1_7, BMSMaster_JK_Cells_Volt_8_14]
BO_ 140 BMSMaster_JK_Cells_Volt_1_7: 7 BMSMaster
 SG_ Voltage_Cell1 : 0|8@1+ (0.01,0) [0|425] "V" Vector__XXX
 SG_ Voltage_Cell2 : 8|8@1+ (0.01,0) [0|425] "V" Vector__XXX
 SG_ Voltage_Cell3 : 16|8@1+ (0.01,0) [0|425] "V" Vector__XXX
 SG_ Voltage_Cell4 : 24|8@1+ (0.01,0) [0|425] "V" Vector__XXX
 SG_ Voltage_Cell5 : 32|8@1+ (0.01,0) [0|425] "V" Vector__XXX
 SG_ Voltage_Cell6 : 40|8@1+ (0.01,0) [0|425] "V" Vector__XXX
 SG_ Voltage_Cell7 : 48|8@1+ (0.01,0) [0|425] "V" Vector__XXX

BO_ 141 BMSMaster_JK_Cells_Volt_8_14: 7 BMSMaster
 SG_ Voltage_Cell8 : 0|8@1+ (0.01,0) [0|425] "V" Vector__XXX
 SG_ Voltage_Cell9 : 8|8@1+ (0.01,0) [0|425] "V" Vector__XXX
 SG_ Voltage_Cell10 : 16|8@1+ (0.01,0) [0|425] "V" Vector__XXX
 SG_ Voltage_Cell11 : 24|8@1+ (0.01,0) [0|425] "V" Vector__XXX
 SG_ Voltage_Cell12 : 32|8@1+ (0.01,0) [0|425] "V" Vector__XXX
 SG_ Voltage_Cell13 : 40|8@1+ (0.01,0) [0|425] "V" Vector__XXX
 SG_ Voltage_Cell14 : 48|8@1+ (0.01,0) [0|425] "V" Vector__XXX

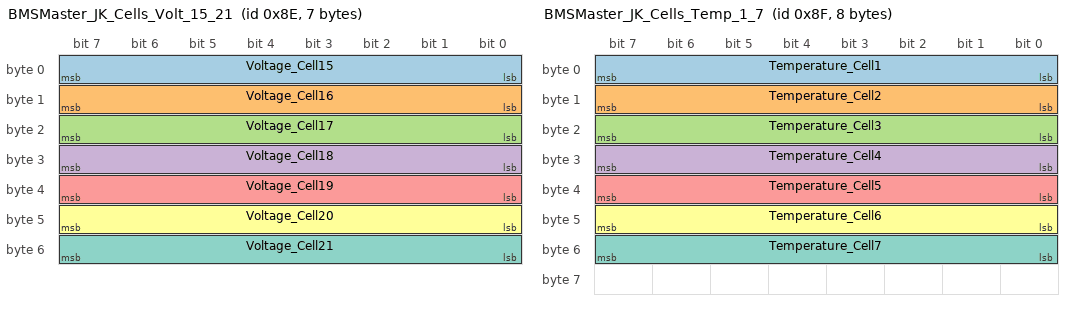
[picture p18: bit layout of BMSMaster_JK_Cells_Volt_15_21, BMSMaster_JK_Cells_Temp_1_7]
BO_ 142 BMSMaster_JK_Cells_Volt_15_21: 7 BMSMaster
 SG_ Voltage_Cell15 : 0|8@1+ (0.01,0) [0|425] "V" Vector__XXX
 SG_ Voltage_Cell16 : 8|8@1+ (0.01,0) [0|425] "V" Vector__XXX
 SG_ Voltage_Cell17 : 16|8@1+ (0.01,0) [0|425] "V" Vector__XXX
 SG_ Voltage_Cell18 : 24|8@1+ (0.01,0) [0|425] "V" Vector__XXX
 SG_ Voltage_Cell19 : 32|8@1+ (0.01,0) [0|425] "V" Vector__XXX
 SG_ Voltage_Cell20 : 40|8@1+ (0.01,0) [0|425] "V" Vector__XXX
 SG_ Voltage_Cell21 : 48|8@1+ (0.01,0) [0|425] "V" Vector__XXX

BO_ 143 BMSMaster_JK_Cells_Temp_1_7: 8 BMSMaster
 SG_ Temperature_Cell1 : 0|8@1+ (1,0) [0|100] "C" Vector__XXX
 SG_ Temperature_Cell2 : 8|8@1+ (1,0) [0|100] "C" Vector__XXX
 SG_ Temperature_Cell3 : 16|8@1+ (1,0) [0|100] "C" Vector__XXX
 SG_ Temperature_Cell4 : 24|8@1+ (1,0) [0|100] "C" Vector__XXX
 SG_ Temperature_Cell5 : 32|8@1+ (1,0) [0|100] "C" Vector__XXX
 SG_ Temperature_Cell6 : 40|8@1+ (1,0) [0|100] "C" Vector__XXX
 SG_ Temperature_Cell7 : 48|8@1+ (1,0) [0|100] "C" Vector__XXX

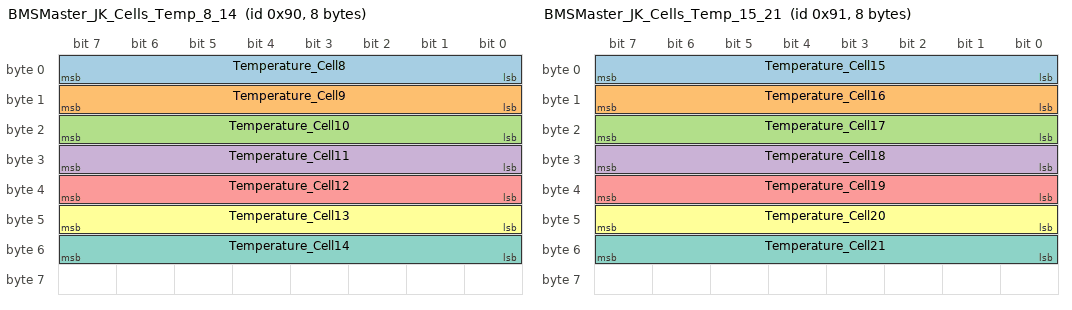
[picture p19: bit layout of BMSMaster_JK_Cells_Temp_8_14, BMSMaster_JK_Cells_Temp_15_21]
BO_ 144 BMSMaster_JK_Cells_Temp_8_14: 8 BMSMaster
 SG_ Temperature_Cell8 : 0|8@1+ (1,0) [0|100] "C" Vector__XXX
 SG_ Temperature_Cell9 : 8|8@1+ (1,0) [0|100] "C" Vector__XXX
 SG_ Temperature_Cell10 : 16|8@1+ (1,0) [0|100] "C" Vector__XXX
 SG_ Temperature_Cell11 : 24|8@1+ (1,0) [0|100] "C" Vector__XXX
 SG_ Temperature_Cell12 : 32|8@1+ (1,0) [0|100] "C" Vector__XXX
 SG_ Temperature_Cell13 : 40|8@1+ (1,0) [0|100] "C" Vector__XXX
 SG_ Temperature_Cell14 : 48|8@1+ (1,0) [0|100] "C" Vector__XXX

BO_ 145 BMSMaster_JK_Cells_Temp_15_21: 8 BMSMaster
 SG_ Temperature_Cell15 : 0|8@1+ (1,0) [0|100] "C" Vector__XXX
 SG_ Temperature_Cell16 : 8|8@1+ (1,0) [0|100] "C" Vector__XXX
 SG_ Temperature_Cell17 : 16|8@1+ (1,0) [0|100] "C" Vector__XXX
 SG_ Temperature_Cell18 : 24|8@1+ (1,0) [0|100] "C" Vector__XXX
 SG_ Temperature_Cell19 : 32|8@1+ (1,0) [0|100] "C" Vector__XXX
 SG_ Temperature_Cell20 : 40|8@1+ (1,0) [0|100] "C" Vector__XXX
 SG_ Temperature_Cell21 : 48|8@1+ (1,0) [0|100] "C" Vector__XXX

BO_ 146 Unnamed: 8 BMSMaster

CM_ SG_ 1696 Error_Code "Error code from csv error file
";
CM_ SG_ 1696 Reserved "Reserved for future use
";
CM_ SG_ 1696 Error_Sprecific_Data "Blob for error specific data (sensor reading, variable dump, etc. - depeneds of error)";
CM_ SG_ 1664 Erro_Code "Error code from csv error file";
CM_ SG_ 1664 Reserved "Reserved for future use
";
CM_ SG_ 1664 Error_Specific_Data "Blob for error specific data (sensor reading, variable dump, etc. - depeneds of error)";
CM_ SG_ 1632 Node_Execution_Halted "Error code from csv error file
";
CM_ SG_ 1632 Reserved "Reserved for future use";
CM_ SG_ 1632 Error_Specific_Data "Blob for error specific data (sensor reading, variable dump, etc. - depeneds of error)";
CM_ SG_ 1600 Error_Code "Error code from csv error file
";
CM_ SG_ 1600 Reserved "Reserved for future use
";
CM_ SG_ 1600 Error_Specific_Data "Blob for error specific data (sensor reading, variable dump, etc. - depeneds of error)";
CM_ SG_ 128 Error_Code "Error code from csv errors file
";
CM_ SG_ 128 Reserved "Reserved for future use";
CM_ SG_ 128 Error_Specific_Data "Blob for error specific data (sensor reading, variable dump, etc. - depeneds of error)";
CM_ SG_ 64 Error_Code "Error code from csv error file
";
CM_ SG_ 64 Reserved "Reserved for future use";
CM_ SG_ 64 Error_Specific_Data "Blob for error specific data (sensor reading, variable dump, etc. - depeneds of error)";
CM_ BO_ 1 "
";
CM_ SG_ 166 LeftMotorErrorMsg "manual p.214
";
CM_ SG_ 167 RightMotorErrorMsg "manual p.214";
CM_ SG_ 2550588916 MaxChargVolt ".1V/byte offset:0 e.g. Vset=3201, its corresponding 320.1V";
CM_ SG_ 2550588916 MaxChargCurr ".1A/byte offset:0 e.g. Iset=582, its corresponding 58.2A";
CM_ SG_ 2550589428 MaxChargVolt ".1V/byte offset:0 e.g. Vset=3201, its corresponding 320.1V";
CM_ SG_ 2550589428 MaxChargCurr ".1A/byte offset:0 e.g. Iset=582, its corresponding 58.2A";
CM_ SG_ 2550589684 MaxChargVolt ".1V/byte offset:0 e.g. Vset=3201, its corresponding 320.1V";
CM_ SG_ 2550589684 MaxChargCurr ".1A/byte offset:0 e.g. Iset=582, its corresponding 58.2A";
CM_ SG_ 130 BMSMaster_MasterBatteryVoltage "Master battery Voltage MSB value which is read by ADC embedded in stm32 core on BMS Masster board";
CM_ SG_ 130 BMSMaster_MasterBatteryCurrent "Master battery Current LSB value which is read by ADC embedded in stm32 core on BMS Masster board";
CM_ SG_ 130 BMSMaste_MasterBatteryTemperatur "Master battery Temperature MSB value which is read by ADC embedded in stm32 core on BMS Masster board";
CM_ SG_ 993 Absolute_Encoder "Validity flag for absolute encoder signal indicating whether the steering position data is correct and usable.";
CM_ SG_ 993 PRND "Gear selector position derived from ADC reading of PRND switch (4 discrete positions).";
CM_ SG_ 994 Rain_Level "Rain intensity level derived from rain sensor measurement, used for automatic wiper control.";
CM_ SG_ 995 Wiper_Slow "Indicates activation of low-speed windshield wiper mode.";
CM_ SG_ 995 Wiper_Fast "Indicates activation of high-speed windshield wiper mode.";
CM_ SG_ 995 Wiper_Rain "Indicates automatic wiper mode activation based on rain sensor input.";
CM_ SG_ 995 Fluid "Windshield washer fluid level status indication.";
CM_ SG_ 995 Mode "Operating mode selection for car permormance.";
CM_ SG_ 995 Turn_Signal_Left "Turn indicator status showing left.
";
CM_ SG_ 995 Turn_Signal_Right "Turn indicator status showing right.
";
CM_ SG_ 995 Emergency "Hazard warning lights activation status.";
CM_ SG_ 65 SteeringWheel "Steering wheel linear potentiometer (LPF 175mm) readout
";
CM_ SG_ 65 BrakesLinear "Brakes linear potentiometers (LPF 25mm) readout
";
CM_ SG_ 65 BrakesHall "Brakes Hall readout
";
CM_ SG_ 65 AccelPedal "Acceleration pedal readout";
CM_ SG_ 0 NMT_Command "0x01 - Go To Operational
0x02 - Go To Stopped
0x80 - Go To Pre-Operational
0x81 - Reset Node";
CM_ SG_ 0 NodeID "Targed NodeID (if send zero, all CANOpen devices will react)";
CM_ SG_ 140 Voltage_Cell1 "Precision up to 0.01V, data is stored from 0 to 4.25V. So if on CAN data is 300, then it's equal to 300 * 0.01 = 3V";
CM_ SG_ 140 Voltage_Cell2 "Precision up to 0.01V, data is stored from 0 to 4.25V. So if on CAN data is 300, then it's equal to 300 * 0.01 = 3V";
CM_ SG_ 140 Voltage_Cell3 "Precision up to 0.01V, data is stored from 0 to 4.25V. So if on CAN data is 300, then it's equal to 300 * 0.01 = 3V";
CM_ SG_ 140 Voltage_Cell4 "Precision up to 0.01V, data is stored from 0 to 4.25V. So if on CAN data is 300, then it's equal to 300 * 0.01 = 3V";
CM_ SG_ 140 Voltage_Cell5 "Precision up to 0.01V, data is stored from 0 to 4.25V. So if on CAN data is 300, then it's equal to 300 * 0.01 = 3V";
CM_ SG_ 140 Voltage_Cell6 "Precision up to 0.01V, data is stored from 0 to 4.25V. So if on CAN data is 300, then it's equal to 300 * 0.01 = 3V";
CM_ SG_ 140 Voltage_Cell7 "Precision up to 0.01V, data is stored from 0 to 4.25V. So if on CAN data is 300, then it's equal to 300 * 0.01 = 3V";
CM_ SG_ 141 Voltage_Cell8 "Precision up to 0.01V, data is stored from 0 to 4.25V. So if on CAN data is 300, then it's equal to 300 * 0.01 = 3V";
CM_ SG_ 141 Voltage_Cell9 "Precision up to 0.01V, data is stored from 0 to 4.25V. So if on CAN data is 300, then it's equal to 300 * 0.01 = 3V";
CM_ SG_ 141 Voltage_Cell10 "Precision up to 0.01V, data is stored from 0 to 4.25V. So if on CAN data is 300, then it's equal to 300 * 0.01 = 3V";
CM_ SG_ 141 Voltage_Cell11 "Precision up to 0.01V, data is stored from 0 to 4.25V. So if on CAN data is 300, then it's equal to 300 * 0.01 = 3V";
CM_ SG_ 141 Voltage_Cell12 "Precision up to 0.01V, data is stored from 0 to 4.25V. So if on CAN data is 300, then it's equal to 300 * 0.01 = 3V";
CM_ SG_ 141 Voltage_Cell13 "Precision up to 0.01V, data is stored from 0 to 4.25V. So if on CAN data is 300, then it's equal to 300 * 0.01 = 3V";
CM_ SG_ 141 Voltage_Cell14 "Precision up to 0.01V, data is stored from 0 to 4.25V. So if on CAN data is 300, then it's equal to 300 * 0.01 = 3V";
CM_ SG_ 142 Voltage_Cell15 "Precision up to 0.01V, data is stored from 0 to 4.25V. So if on CAN data is 300, then it's equal to 300 * 0.01 = 3V";
CM_ SG_ 142 Voltage_Cell16 "Precision up to 0.01V, data is stored from 0 to 4.25V. So if on CAN data is 300, then it's equal to 300 * 0.01 = 3V";
CM_ SG_ 142 Voltage_Cell17 "Precision up to 0.01V, data is stored from 0 to 4.25V. So if on CAN data is 300, then it's equal to 300 * 0.01 = 3V";
CM_ SG_ 142 Voltage_Cell18 "Precision up to 0.01V, data is stored from 0 to 4.25V. So if on CAN data is 300, then it's equal to 300 * 0.01 = 3V";
CM_ SG_ 142 Voltage_Cell19 "Precision up to 0.01V, data is stored from 0 to 4.25V. So if on CAN data is 300, then it's equal to 300 * 0.01 = 3V";
CM_ SG_ 142 Voltage_Cell20 "Precision up to 0.01V, data is stored from 0 to 4.25V. So if on CAN data is 300, then it's equal to 300 * 0.01 = 3V";
CM_ SG_ 142 Voltage_Cell21 "Precision up to 0.01V, data is stored from 0 to 4.25V. So if on CAN data is 300, then it's equal to 300 * 0.01 = 3V";
CM_ SG_ 143 Temperature_Cell1 "`";
BA_DEF_ BO_  "GenMsgCycleTime" INT 1 50000;
BA_DEF_ SG_  "SystemSignalLongSymbol" STRING ;
BA_DEF_DEF_  "GenMsgCycleTime" 100;
BA_DEF_DEF_  "SystemSignalLongSymbol" "";
BA_ "GenMsgCycleTime" BO_ 192 2000;
BA_ "GenMsgCycleTime" BO_ 128 5000;
BA_ "GenMsgCycleTime" BO_ 159 1000;
BA_ "GenMsgCycleTime" BO_ 2550588916 1000;
BA_ "GenMsgCycleTime" BO_ 2550589428 1000;
BA_ "GenMsgCycleTime" BO_ 2550589684 1000;
BA_ "GenMsgCycleTime" BO_ 130 500;
BA_ "GenMsgCycleTime" BO_ 131 1000;
BA_ "GenMsgCycleTime" BO_ 132 1000;
BA_ "GenMsgCycleTime" BO_ 133 1000;
BA_ "GenMsgCycleTime" BO_ 134 1000;
BA_ "GenMsgCycleTime" BO_ 135 1000;
BA_ "GenMsgCycleTime" BO_ 136 1000;
BA_ "GenMsgCycleTime" BO_ 137 1000;
BA_ "GenMsgCycleTime" BO_ 138 1000;
BA_ "GenMsgCycleTime" BO_ 139 1000;
BA_ "SystemSignalLongSymbol" SG_ 1248 CoolingBack_Node_Execution__0002 "CoolingBack_Node_Execution_Halted";
BA_ "SystemSignalLongSymbol" SG_ 1280 CoolingLeft_Node_Execution__0001 "CoolingLeft_Node_Execution_Halted";
BA_ "SystemSignalLongSymbol" SG_ 1344 CoolingMotor_Node_Execution_0003 "CoolingMotor_Node_Execution_Halted";
BA_ "SystemSignalLongSymbol" SG_ 1312 CoolingRight_Node_Execution_0004 "CoolingRight_Node_Execution_Halted";
BA_ "GenMsgCycleTime" BO_ 193 1000;
BA_ "GenMsgCycleTime" BO_ 140 1000;
BA_ "GenMsgCycleTime" BO_ 141 1000;
BA_ "GenMsgCycleTime" BO_ 142 1000;
BA_ "GenMsgCycleTime" BO_ 143 1000;
BA_ "GenMsgCycleTime" BO_ 144 1000;
BA_ "GenMsgCycleTime" BO_ 145 1000;
BA_ "GenMsgCycleTime" BO_ 146 1000;
VAL_ 2566869221 Charger1HardwareFailure 0 "Normal" 1 "Hardware failure" ;
VAL_ 2566869221 Charger1Temperature 0 "Normal" 1 "Over temp protection" ;
VAL_ 2566869221 Charger1InputVoltage 0 "Normal" 1 "Wrong" ;
VAL_ 2566869221 Charger1StaringState 0 "Charging" 1 "Turn off" ;
VAL_ 2566869221 Charger1CommunicationState 0 "Normal" 1 "Time-out" ;
VAL_ 1830 LeftMotorNMTState 0 "BootUp" 4 "Stopped" 5 "Operational" 127 "Pre-Operational" ;
VAL_ 1831 RightMotorNMTState 9 "BootUp" 4 "Stopped" 5 "Operational" 127 "Pre-Operational" ;
VAL_ 2566869223 Charger2HardwareFailure 0 "Normal" 1 "Hardware failure" ;
VAL_ 2566869223 Charger2Temperature 0 "Normal" 1 "Over temp protection" ;
VAL_ 2566869223 Charger2InputVoltage 0 "Normal" 1 "Wrong" ;
VAL_ 2566869223 Charger2StaringState 0 "Charging" 1 "Turn off" ;
VAL_ 2566869223 Charger2CommunicationState 0 "Normal" 1 "Time-out" ;
VAL_ 2566869224 Charger3HardwareFailure 0 "Normal" 1 "Hardware failure" ;
VAL_ 2566869224 Charger3Temperature 0 "Normal" 1 "Over temp protection" ;
VAL_ 2566869224 Charger3InputVoltage 0 "Normal" 1 "Wrong" ;
VAL_ 2566869224 Charger3StaringState 0 "Charging" 1 "Turn off" ;
VAL_ 2566869224 Charger3CommunicationState 0 "Normal" 1 "Time-out" ;
VAL_ 2550588916 Control 1 "Stop charging" 0 "Start charging" ;
VAL_ 2550589428 Control 0 "Start charging" 1 "Stop charging" ;
VAL_ 2550589684 Control 1 "Stop charging" 0 "Start charging" ;
VAL_ 994 Light_Switch 0 "Off" 1 "Position" 2 "Low beam" 3 "High beam" ;
VAL_ 994 Rain_Level 0 "off" 1 "Light" 2 "Medium" 3 "Heavy" ;
VAL_ 995 Wiper_Slow 0 "Off" 1 "On" ;
VAL_ 995 Wiper_Fast 0 "Off" 1 "On" ;
VAL_ 995 Wiper_Rain 0 "Off" 1 "On" ;
VAL_ 995 Fluid 0 "Off" 1 "On" ;
VAL_ 995 Mode 0 "Normal" 1 "Expensive" ;
VAL_ 995 Turn_Signal_Left 0 "Off" 1 "On" ;
VAL_ 995 Turn_Signal_Right 1 "On" 0 "Off" ;
VAL_ 1857 smallLens1 1 "On" 0 "Off" ;
VAL_ 1857 smallLens2 1 "On" 0 "Off" ;
VAL_ 1857 direction 1 "On" 0 "Off" ;
VAL_ 1857 day 1 "On" 0 "Off" ;
VAL_ 1857 sideDirection 1 "On" 0 "Off" ;
VAL_ 1857 headlights 1 "On" 0 "Off" ;
VAL_ 1857 highBeams 1 "On" 0 "Off" ;
VAL_ 1889 smallLens1 1 "On" 0 "Off" ;
VAL_ 1889 smallLens2 1 "On" 0 "Off" ;
VAL_ 1889 direction 1 "On" 0 "Off" ;
VAL_ 1889 day 1 "On" 0 "Off" ;
VAL_ 1889 sideDirection 1 "On" 0 "Off" ;
VAL_ 1889 headlights 1 "On" 0 "Off" ;
VAL_ 1889 highBeams 1 "On" 0 "Off" ;
VAL_ 1921 reverse 1 "On" 0 "Off" ;
VAL_ 1921 sideStop 1 "On" 0 "Off" ;
VAL_ 1921 direction 1 "On" 0 "Off" ;
VAL_ 1921 positionCircles 1 "On" 0 "Off" ;
VAL_ 1921 safeState 1 "On" 0 "Off" ;
VAL_ 1921 middleStop 1 "On" 0 "Off" ;
VAL_ 1921 positionSide 1 "On" 0 "Off" ;
VAL_ 1953 reverse 1 "On" 0 "Off" ;
VAL_ 1953 sideStop 1 "On" 0 "Off" ;
VAL_ 1953 direction 1 "On" 0 "Off" ;
VAL_ 1953 positionCircles 1 "On" 0 "Off" ;
VAL_ 1953 safeState 1 "On" 0 "Off" ;
VAL_ 1953 positionWhole 1 "On" 0 "Off" ;
VAL_ 1953 positionSide 1 "On" 0 "Off" ;
VAL_ 193 ChargingPortStatus 0 "Disconnected" 1 "Connected" 2 "Charging" ;
